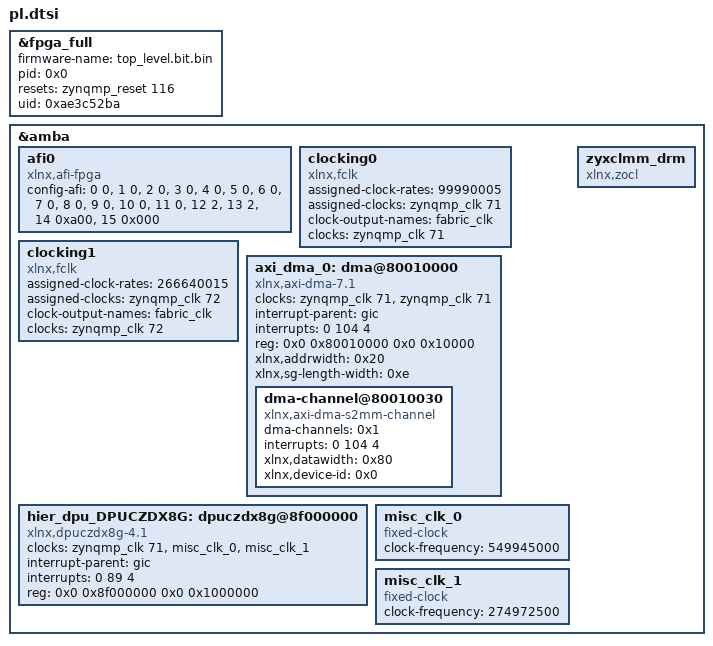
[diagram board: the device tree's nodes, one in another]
/*
 * CAUTION: This file is automatically generated by Xilinx.
 * Version: XSCT 2022.2
 * Today is: Tue Dec 16 06:17:22 2025
 */


/dts-v1/;
/plugin/;
/ {
	fragment@0 {
		target = <&fpga_full>;
		overlay0: __overlay__ {
			#address-cells = <2>;
			#size-cells = <2>;
			firmware-name = "top_level.bit.bin";
			pid = <0x0>;
			resets = <&zynqmp_reset 116>;
			uid = <0xae3c52ba>;
		};
	};
	fragment@1 {
		target = <&amba>;
		overlay1: __overlay__ {
			afi0: afi0 {
				compatible = "xlnx,afi-fpga";
				config-afi = < 0 0>, <1 0>, <2 0>, <3 0>, <4 0>, <5 0>, <6 0>, <7 0>, <8 0>, <9 0>, <10 0>, <11 0>, <12 2>, <13 2>, <14 0xa00>, <15 0x000>;
			};
			clocking0: clocking0 {
				#clock-cells = <0>;
				assigned-clock-rates = <99990005>;
				assigned-clocks = <&zynqmp_clk 71>;
				clock-output-names = "fabric_clk";
				clocks = <&zynqmp_clk 71>;
				compatible = "xlnx,fclk";
			};
			clocking1: clocking1 {
				#clock-cells = <0>;
				assigned-clock-rates = <266640015>;
				assigned-clocks = <&zynqmp_clk 72>;
				clock-output-names = "fabric_clk";
				clocks = <&zynqmp_clk 72>;
				compatible = "xlnx,fclk";
			};
		};
	};
	fragment@2 {
		target = <&amba>;
		overlay2: __overlay__ {
			#address-cells = <2>;
			#size-cells = <2>;
			axi_dma_0: dma@80010000 {
				#dma-cells = <1>;
				clock-names = "s_axi_lite_aclk", "m_axi_s2mm_aclk";
				clocks = <&zynqmp_clk 71>, <&zynqmp_clk 71>;
				compatible = "xlnx,axi-dma-7.1", "xlnx,axi-dma-1.00.a";
				interrupt-names = "s2mm_introut";
				interrupt-parent = <&gic>;
				interrupts = <0 104 4>;
				reg = <0x0 0x80010000 0x0 0x10000>;
				xlnx,addrwidth = <0x20>;
				xlnx,sg-length-width = <0xe>;
				dma-channel@80010030 {
					compatible = "xlnx,axi-dma-s2mm-channel";
					dma-channels = <0x1>;
					interrupts = <0 104 4>;
					xlnx,datawidth = <0x80>;
					xlnx,device-id = <0x0>;
				};
			};
			hier_dpu_DPUCZDX8G: dpuczdx8g@8f000000 {
				/* This is a place holder node for a custom IP, user may need to update the entries */
				clock-names = "s_axi_aclk", "dpu_2x_clk", "m_axi_dpu_aclk";
				clocks = <&zynqmp_clk 71>, <&misc_clk_0>, <&misc_clk_1>;
				compatible = "xlnx,dpuczdx8g-4.1";
				interrupt-names = "dpu0_interrupt";
				interrupt-parent = <&gic>;
				interrupts = <0 89 4>;
				reg = <0x0 0x8f000000 0x0 0x1000000>;
			};
			misc_clk_0: misc_clk_0 {
				#clock-cells = <0>;
				clock-frequency = <549945000>;
				compatible = "fixed-clock";
			};
			misc_clk_1: misc_clk_1 {
				#clock-cells = <0>;
				clock-frequency = <274972500>;
				compatible = "fixed-clock";
			};
			zyxclmm_drm {
				compatible = "xlnx,zocl";
			};
		};
	};
};
